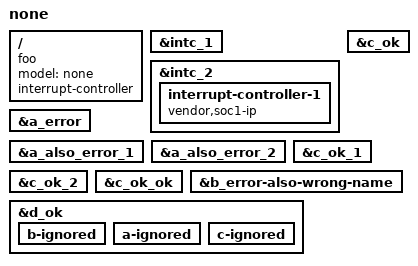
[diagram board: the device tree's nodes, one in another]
// SPDX-License-Identifier: BSD-2-Clause
/dts-v1/;
/ {
	model = "none";
	compatible = "foo";

	#address-cells = <1>;
	#size-cells = <1>;

	interrupt-controller;
	#interrupt-cells = <1>;
};

&intc_1 {
	status = "okay";
};

&intc_2 { // Comment
	status = "okay";

	interrupt-controller-1 {
		compatible = "vendor,soc1-ip";
	};
};

&a_error {
	status = "okay";
};

&a_also_error_1 { // Comment
	status = "okay";
};

&c_ok {
	status = "okay";
};

&a_also_error_2 { /* Comment */
	status = "okay";
};

&c_ok_1 {
	status = "okay";
};

&c_ok_2 { // ok
	status = "okay";
};

&c_ok_ok {
	status = "okay";
};

&b_error-also-wrong-name {
	status = "okay";
};

&d_ok {
	b-ignored {
		status = "okay";
	};

	a-ignored {
		status = "okay";
	};

	c-ignored { /* comment */
		status = "okay";
	};
}
